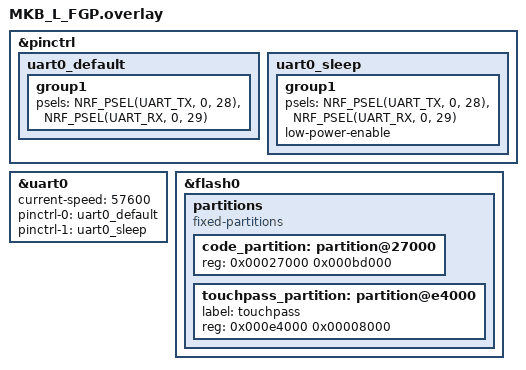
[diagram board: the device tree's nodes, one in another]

&pinctrl {
    uart0_default: uart0_default {
        group1 {
            psels = <NRF_PSEL(UART_TX, 0, 28)>,
                    <NRF_PSEL(UART_RX, 0, 29)>;
        };
    };
    uart0_sleep: uart0_sleep {
        group1 {
            psels = <NRF_PSEL(UART_TX, 0, 28)>,
                    <NRF_PSEL(UART_RX, 0, 29)>;
            low-power-enable;
        };
    };
};

&uart0 {
    status = "okay";
    current-speed = <57600>;
    pinctrl-0 = <&uart0_default>;
    pinctrl-1 = <&uart0_sleep>;
    pinctrl-names = "default", "sleep";
};

// パーティションの再定義
&flash0 {
    partitions {
        compatible = "fixed-partitions";
        #address-cells = <1>;
        #size-cells = <1>;

        // code_partition を縮小して領域を空ける (0x27000 + 0xbd000 = 0xe4000)
        code_partition: partition@27000 {
            reg = <0x00027000 0x000bd000>;
        };

        touchpass_partition: partition@e4000 {
            label = "touchpass";
            reg = <0x000e4000 0x00008000>;
        };
    };
};
